# PIC32MX274F256B register map
Registers are 32-bit, access not given, reset 0x0 unless marked. A register's access mark holds for its fields unless they carry their own. Offsets are from the block's base; [hi:lo] are bit positions; {n}, {i} and the like mark numbered series; 'fields as' and 'values as' point back to an identical list.

## CFG — CFG peripheral
Base 0xBF80F200
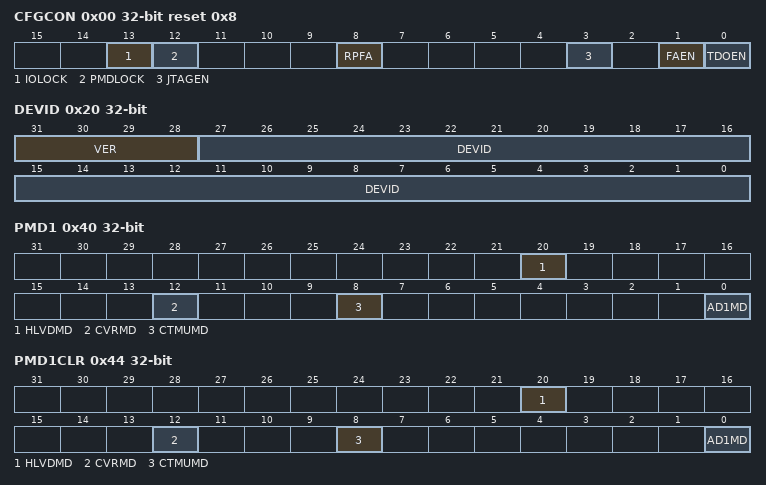
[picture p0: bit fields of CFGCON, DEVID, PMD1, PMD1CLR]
0x00 CFGCON reset 0x8
  [13] IOLOCK, [12] PMDLOCK, [8] RPFA, [3] JTAGEN, [1] FAEN, [0] TDOEN
0x20 DEVID
  [31:28] VER, [27:0] DEVID
0x30 SYSKEY
0x34 SYSKEYCLR
  [31:0] SYSKEY
0x38 SYSKEYSET
  [31:0] SYSKEY
0x3C SYSKEYINV
  [31:0] SYSKEY
0x40 PMD1
  [20] HLVDMD, [12] CVRMD, [8] CTMUMD, [0] AD1MD
0x44 PMD1CLR
  [20] HLVDMD, [12] CVRMD, [8] CTMUMD, [0] AD1MD
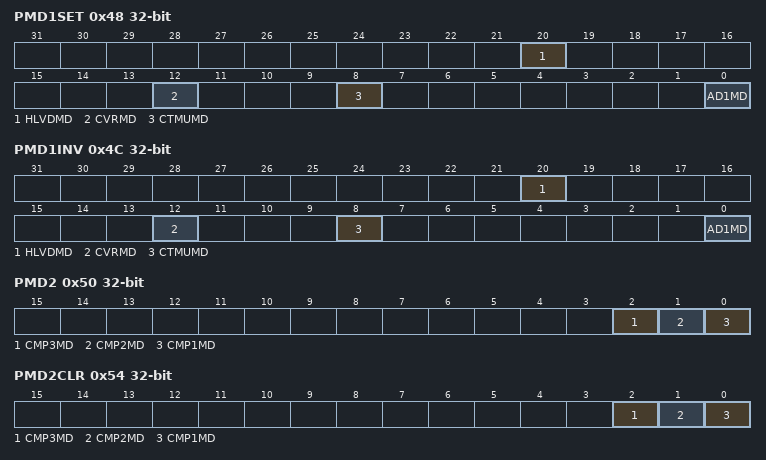
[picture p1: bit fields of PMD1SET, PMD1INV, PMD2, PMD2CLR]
0x48 PMD1SET
  [20] HLVDMD, [12] CVRMD, [8] CTMUMD, [0] AD1MD
0x4C PMD1INV
  [20] HLVDMD, [12] CVRMD, [8] CTMUMD, [0] AD1MD
0x50 PMD2
  [2] CMP3MD, [1] CMP2MD, [0] CMP1MD
0x54 PMD2CLR
  [2] CMP3MD, [1] CMP2MD, [0] CMP1MD
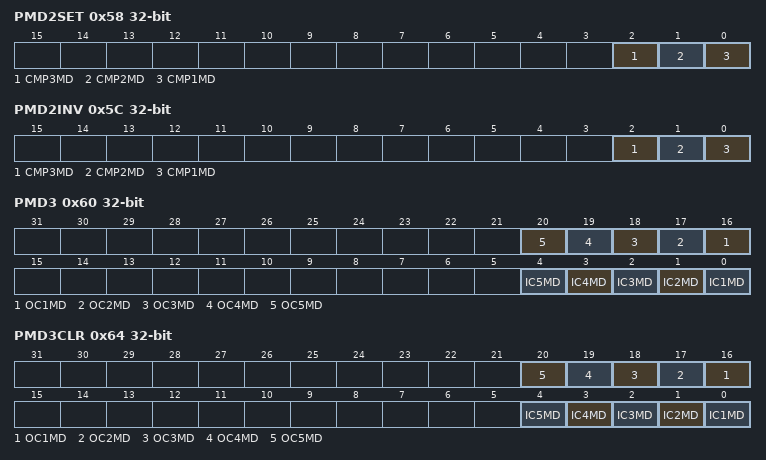
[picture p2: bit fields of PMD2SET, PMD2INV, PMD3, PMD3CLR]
0x58 PMD2SET
  [2] CMP3MD, [1] CMP2MD, [0] CMP1MD
0x5C PMD2INV
  [2] CMP3MD, [1] CMP2MD, [0] CMP1MD
0x60 PMD3
  [n+15] OC{n}MD (n=1..5), [n-1] IC{n}MD (n=1..5)
0x64 PMD3CLR
  [n+15] OC{n}MD (n=1..5), [n-1] IC{n}MD (n=1..5)
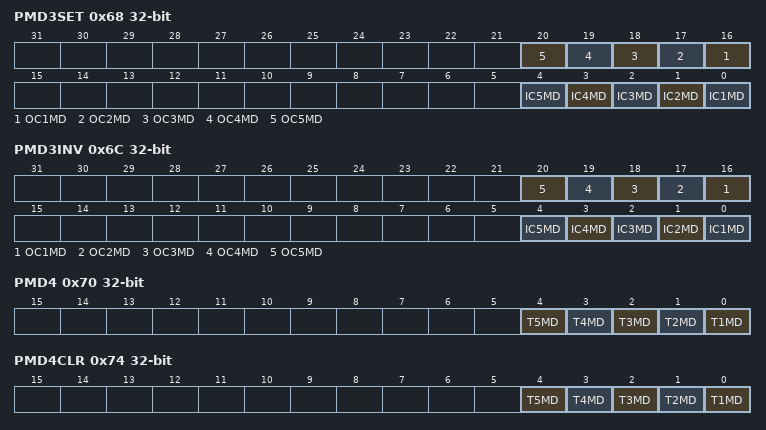
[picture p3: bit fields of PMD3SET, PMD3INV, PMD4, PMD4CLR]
0x68 PMD3SET
  [n+15] OC{n}MD (n=1..5), [n-1] IC{n}MD (n=1..5)
0x6C PMD3INV
  [n+15] OC{n}MD (n=1..5), [n-1] IC{n}MD (n=1..5)
0x70 PMD4
  [n-1] T{n}MD (n=1..5)
0x74 PMD4CLR
  [n-1] T{n}MD (n=1..5)
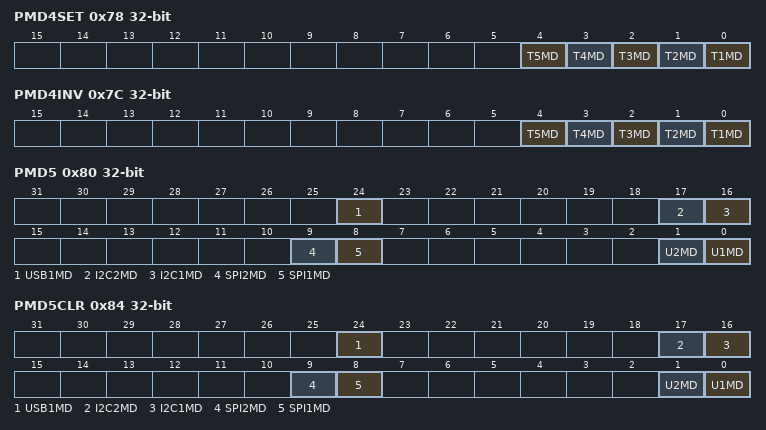
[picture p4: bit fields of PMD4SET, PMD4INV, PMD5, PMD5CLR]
0x78 PMD4SET
  [n-1] T{n}MD (n=1..5)
0x7C PMD4INV
  [n-1] T{n}MD (n=1..5)
0x80 PMD5
  [24] USB1MD, [17] I2C2MD, [16] I2C1MD, [9] SPI2MD, [8] SPI1MD, [1] U2MD, [0] U1MD
0x84 PMD5CLR
  fields as PMD5
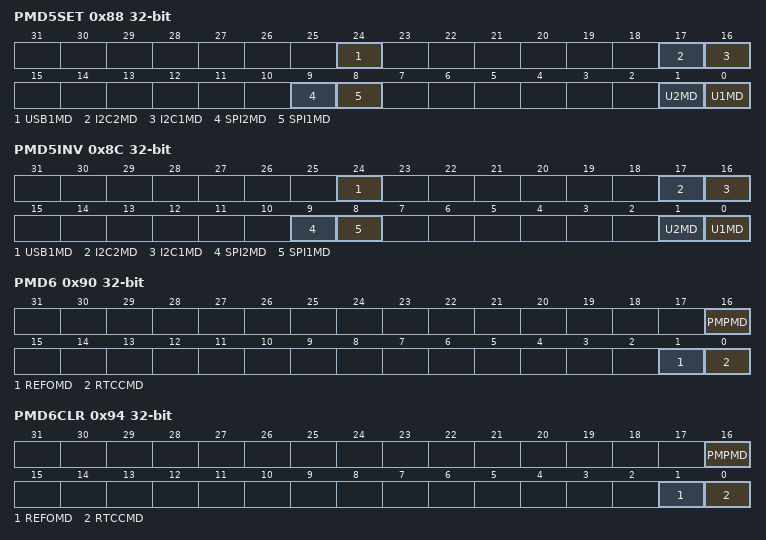
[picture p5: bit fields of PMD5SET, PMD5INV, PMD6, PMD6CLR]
0x88 PMD5SET
  fields as PMD5
0x8C PMD5INV
  fields as PMD5
0x90 PMD6
  [16] PMPMD, [1] REFOMD, [0] RTCCMD
0x94 PMD6CLR
  [16] PMPMD, [1] REFOMD, [0] RTCCMD
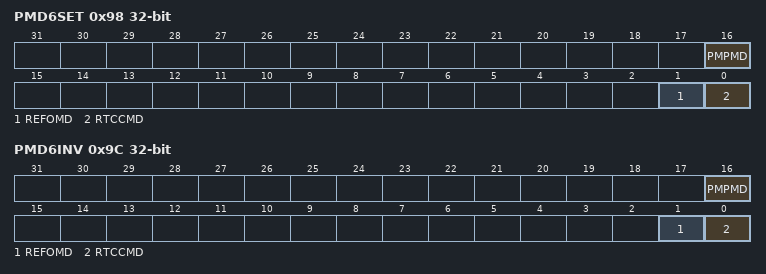
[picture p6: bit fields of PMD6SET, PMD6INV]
0x98 PMD6SET
  [16] PMPMD, [1] REFOMD, [0] RTCCMD
0x9C PMD6INV
  [16] PMPMD, [1] REFOMD, [0] RTCCMD

## NVM — NVM peripheral
Base 0xBF80F400
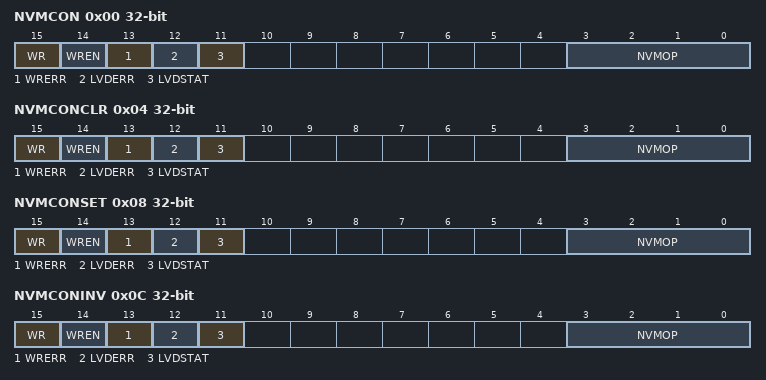
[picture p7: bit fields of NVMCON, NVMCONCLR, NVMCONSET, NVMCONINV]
0x00 NVMCON
  [15] WR, [14] WREN, [13] WRERR, [12] LVDERR, [11] LVDSTAT, [3:0] NVMOP
0x04 NVMCONCLR
  fields as NVMCON
0x08 NVMCONSET
  fields as NVMCON
0x0C NVMCONINV
  fields as NVMCON
0x10 NVMKEY
0x20 NVMADDR
0x24 NVMADDRCLR
  [31:0] NVMADDR
0x28 NVMADDRSET
  [31:0] NVMADDR
0x2C NVMADDRINV
  [31:0] NVMADDR
0x30 NVMDATA
0x40 NVMSRCADDR

## WDT — WDT peripheral
Base 0xBF80F600
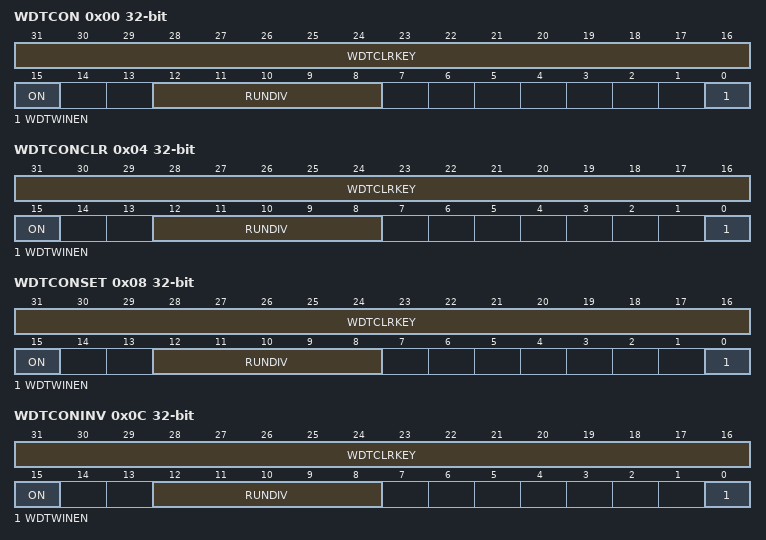
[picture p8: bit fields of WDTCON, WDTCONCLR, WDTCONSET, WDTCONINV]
0x00 WDTCON
  [31:16] WDTCLRKEY, [15] ON, [12:8] RUNDIV, [0] WDTWINEN
0x04 WDTCONCLR
  [31:16] WDTCLRKEY, [15] ON, [12:8] RUNDIV, [0] WDTWINEN
0x08 WDTCONSET
  [31:16] WDTCLRKEY, [15] ON, [12:8] RUNDIV, [0] WDTWINEN
0x0C WDTCONINV
  [31:16] WDTCLRKEY, [15] ON, [12:8] RUNDIV, [0] WDTWINEN

## PPS — PPS peripheral
Base 0xBF80FA04
0x00 INT1R
  [3:0] INT1R
0x04 INT2R
  [3:0] INT2R
0x08 INT3R
  [3:0] INT3R
0x0C INT4R
  [3:0] INT4R
{0xC+4i} T{i}CKR (i=2..5)
  [3:0] T{i}CKR
{0x20+4i} IC{i}R (i=1..5)
  [3:0] IC{i}R
0x44 OCFAR
  [3:0] OCFAR
0x48 OCFBR
  [3:0] OCFBR
0x4C U1RXR
  [3:0] U1RXR
0x50 U1CTSR
  [3:0] U1CTSR
0x54 U2RXR
  [3:0] U2RXR
0x58 U2CTSR
  [3:0] U2CTSR
0x80 SDI1R
  [3:0] SDI1R
0x84 SS1R
  [3:0] SS1R
0x8C SDI2R
  [3:0] SDI2R
0x90 SS2R
  [3:0] SS2R
0xB4 REFCLKIR
  [3:0] REFCLKIR
{0xFC+4i} RPA{i}R (i=0..4)
  [3:0] RPA{i}R
0x11C RPA8R
  [3:0] RPA8R
0x120 RPA9R
  [3:0] RPA9R
{0x128+4i} RPB{i}R (i=0..11)
  [3:0] RPB{i}R
{0x128+4i} RPB{i}R (i=13..15)
  [3:0] RPB{i}R
{0x168+4i} RPC{i}R (i=0..9)
  [3:0] RPC{i}R

## HLVD — HLVD peripheral
Base 0xBF80FC00
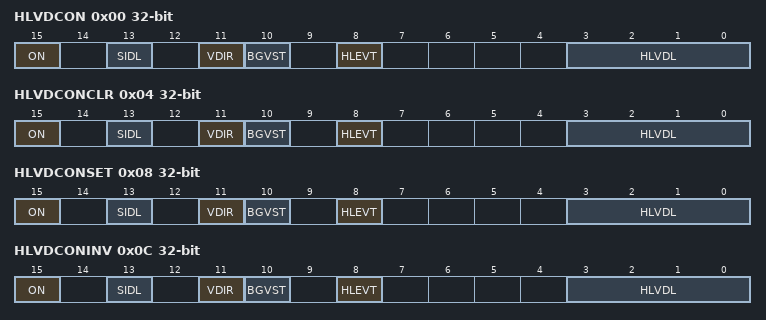
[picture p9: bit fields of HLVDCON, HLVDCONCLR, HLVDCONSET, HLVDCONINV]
0x00 HLVDCON
  [15] ON, [13] SIDL, [11] VDIR, [10] BGVST, [8] HLEVT, [3:0] HLVDL
0x04 HLVDCONCLR
  [15] ON, [13] SIDL, [11] VDIR, [10] BGVST, [8] HLEVT, [3:0] HLVDL
0x08 HLVDCONSET
  [15] ON, [13] SIDL, [11] VDIR, [10] BGVST, [8] HLEVT, [3:0] HLVDL
0x0C HLVDCONINV
  [15] ON, [13] SIDL, [11] VDIR, [10] BGVST, [8] HLEVT, [3:0] HLVDL

## BMX — BMX peripheral
Base 0xBF882000
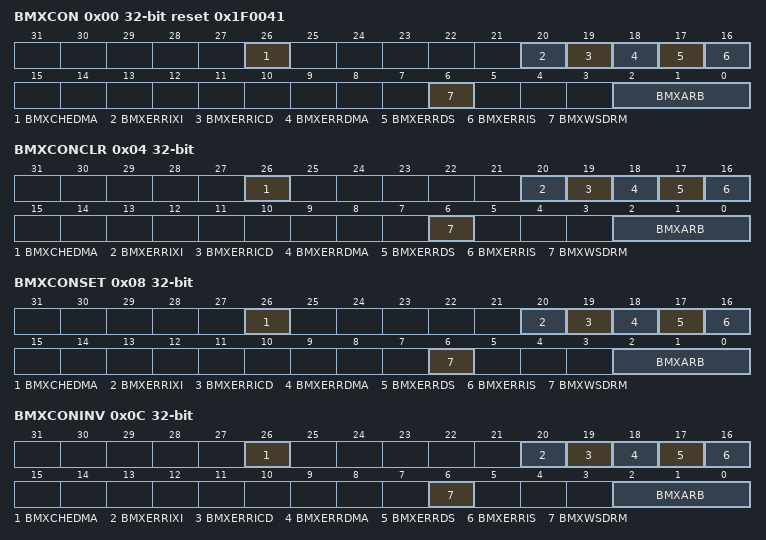
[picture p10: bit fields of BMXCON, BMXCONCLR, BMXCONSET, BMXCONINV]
0x00 BMXCON reset 0x1F0041
  [26] BMXCHEDMA, [20] BMXERRIXI, [19] BMXERRICD, [18] BMXERRDMA, [17] BMXERRDS, [16] BMXERRIS, [6] BMXWSDRM, [2:0] BMXARB
0x04 BMXCONCLR
  fields as BMXCON
0x08 BMXCONSET
  fields as BMXCON
0x0C BMXCONINV
  fields as BMXCON
0x10 BMXDKPBA
0x14 BMXDKPBACLR
  [31:0] BMXDKPBA
0x18 BMXDKPBASET
  [31:0] BMXDKPBA
0x1C BMXDKPBAINV
  [31:0] BMXDKPBA
0x20 BMXDUDBA
0x24 BMXDUDBACLR
  [31:0] BMXDUDBA
0x28 BMXDUDBASET
  [31:0] BMXDUDBA
0x2C BMXDUDBAINV
  [31:0] BMXDUDBA
0x30 BMXDUPBA
0x34 BMXDUPBACLR
  [31:0] BMXDUPBA
0x38 BMXDUPBASET
  [31:0] BMXDUPBA
0x3C BMXDUPBAINV
  [31:0] BMXDUPBA
0x40 BMXDRMSZ reset 0x20000
0x50 BMXPUPBA
0x54 BMXPUPBACLR
  [31:0] BMXPUPBA
0x58 BMXPUPBASET
  [31:0] BMXPUPBA
0x5C BMXPUPBAINV
  [31:0] BMXPUPBA
0x60 BMXPFMSZ reset 0x80000
0x70 BMXBOOTSZ reset 0x3000
